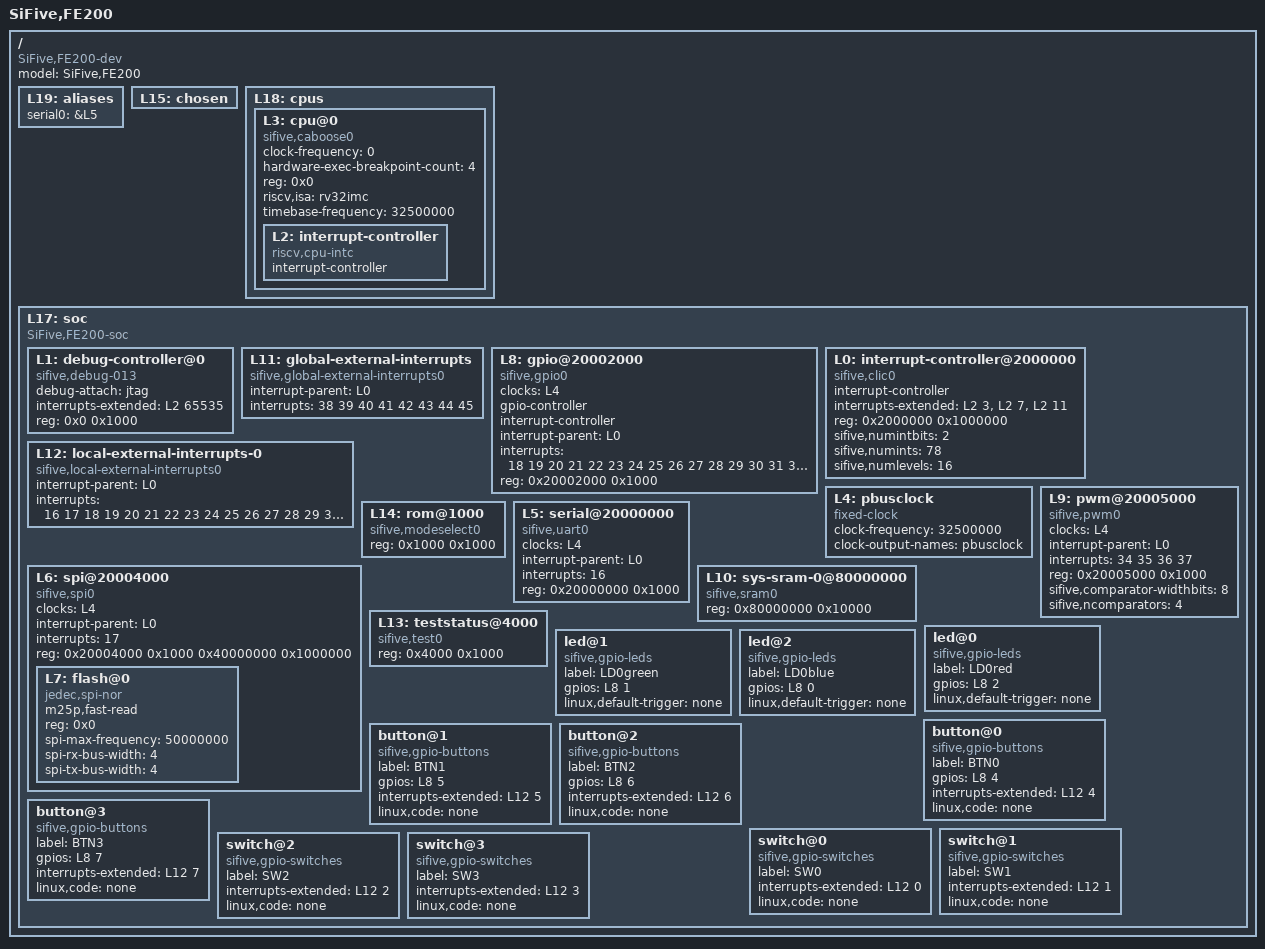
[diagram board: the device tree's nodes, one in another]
/dts-v1/;

/ {
	#address-cells = <1>;
	#size-cells = <1>;
	compatible = "SiFive,FE200-dev", "fe200-dev", "sifive-dev";
	model = "SiFive,FE200";
	L19: aliases {
		serial0 = &L5;
	};
	L15: chosen {
	};
	L18: cpus {
		#address-cells = <1>;
		#size-cells = <0>;
		L3: cpu@0 {
			clock-frequency = <0>;
			compatible = "sifive,caboose0", "riscv";
			device_type = "cpu";
			hardware-exec-breakpoint-count = <4>;
			reg = <0x0>;
			riscv,isa = "rv32imc";
			status = "okay";
			timebase-frequency = <32500000>;
			L2: interrupt-controller {
				#interrupt-cells = <1>;
				compatible = "riscv,cpu-intc";
				interrupt-controller;
			};
		};
	};
	L17: soc {
		#address-cells = <1>;
		#size-cells = <1>;
		compatible = "SiFive,FE200-soc", "fe200-soc", "sifive-soc", "simple-bus";
		ranges;
		L1: debug-controller@0 {
			compatible = "sifive,debug-013", "riscv,debug-013";
			debug-attach = "jtag";
			interrupts-extended = <&L2 65535>;
			reg = <0x0 0x1000>;
			reg-names = "control";
		};
		L11: global-external-interrupts {
			compatible = "sifive,global-external-interrupts0";
			interrupt-parent = <&L0>;
			interrupts = <38 39 40 41 42 43 44 45>;
		};
		L8: gpio@20002000 {
			#gpio-cells = <2>;
			#interrupt-cells = <2>;
			clocks = <&L4>;
			compatible = "sifive,gpio0", "sifive,gpio1";
			gpio-controller;
			interrupt-controller;
			interrupt-parent = <&L0>;
			interrupts = <18 19 20 21 22 23 24 25 26 27 28 29 30 31 32 33>;
			reg = <0x20002000 0x1000>;
			reg-names = "control";
		};
		L0: interrupt-controller@2000000 {
			#interrupt-cells = <1>;
			compatible = "sifive,clic0";
			interrupt-controller;
			interrupts-extended = <&L2 3 &L2 7 &L2 11>;
			reg = <0x2000000 0x1000000>;
			reg-names = "control";
			sifive,numintbits = <2>;
			sifive,numints = <78>;
			sifive,numlevels = <16>;
		};
		L12: local-external-interrupts-0 {
			compatible = "sifive,local-external-interrupts0";
			interrupt-parent = <&L0>;
			interrupts = <16 17 18 19 20 21 22 23 24 25 26 27 28 29 30 31 32 33 34 35 36 37 38 39 40 41 42 43 44 45 46 47>;
		};
		L4: pbusclock {
			#clock-cells = <0>;
			clock-frequency = <32500000>;
			clock-output-names = "pbusclock";
			compatible = "fixed-clock";
		};
		L9: pwm@20005000 {
			clocks = <&L4>;
			compatible = "sifive,pwm0";
			interrupt-parent = <&L0>;
			interrupts = <34 35 36 37>;
			reg = <0x20005000 0x1000>;
			reg-names = "control";
			sifive,comparator-widthbits = <8>;
			sifive,ncomparators = <4>;
		};
		L14: rom@1000 {
			compatible = "sifive,modeselect0";
			reg = <0x1000 0x1000>;
			reg-names = "mem";
		};
		L5: serial@20000000 {
			clocks = <&L4>;
			compatible = "sifive,uart0";
			interrupt-parent = <&L0>;
			interrupts = <16>;
			reg = <0x20000000 0x1000>;
			reg-names = "control";
		};
		L6: spi@20004000 {
			#address-cells = <1>;
			#size-cells = <0>;
			clocks = <&L4>;
			compatible = "sifive,spi0";
			interrupt-parent = <&L0>;
			interrupts = <17>;
			reg = <0x20004000 0x1000 0x40000000 0x1000000>;
			reg-names = "control", "mem";
			L7: flash@0 {
				compatible = "jedec,spi-nor";
				m25p,fast-read;
				reg = <0x0>;
				spi-max-frequency = <50000000>;
				spi-rx-bus-width = <4>;
				spi-tx-bus-width = <4>;
			};
		};
		L10: sys-sram-0@80000000 {
			compatible = "sifive,sram0";
			reg = <0x80000000 0x10000>;
			reg-names = "mem";
		};
		L13: teststatus@4000 {
			compatible = "sifive,test0";
			reg = <0x4000 0x1000>;
			reg-names = "control";
		};
				led@0 {
						compatible = "sifive,gpio-leds";
						label = "LD0red";
						gpios = <&L8 2>;
						linux,default-trigger = "none";
				};
				led@1 {
						compatible = "sifive,gpio-leds";
						label = "LD0green";
						gpios = <&L8 1>;
						linux,default-trigger = "none";
				};
				led@2 {
						compatible = "sifive,gpio-leds";
						label = "LD0blue";
						gpios = <&L8 0>;
						linux,default-trigger = "none";
				};
				button@0 {
						compatible = "sifive,gpio-buttons";
						label = "BTN0";
						gpios = <&L8 4>;
						interrupts-extended = <&L12 4>;
						linux,code = "none";
				};
				button@1 {
						compatible = "sifive,gpio-buttons";
						label = "BTN1";
						gpios = <&L8 5>;
						interrupts-extended = <&L12 5>;
						linux,code = "none";
				};
				button@2 {
						compatible = "sifive,gpio-buttons";
						label = "BTN2";
						gpios = <&L8 6>;
						interrupts-extended = <&L12 6>;
						linux,code = "none";
				};
				button@3 {
						compatible = "sifive,gpio-buttons";
						label = "BTN3";
						gpios = <&L8 7>;
						interrupts-extended = <&L12 7>;
						linux,code = "none";
				};
				switch@0 {
						compatible = "sifive,gpio-switches";
						label = "SW0";
						interrupts-extended = <&L12 0>;
						linux,code = "none";
				};
				switch@1 {
						compatible = "sifive,gpio-switches";
						label = "SW1";
						interrupts-extended = <&L12 1>;
						linux,code = "none";
				};
				switch@2 {
						compatible = "sifive,gpio-switches";
						label = "SW2";
						interrupts-extended = <&L12 2>;
						linux,code = "none";
				};
				switch@3 {
						compatible = "sifive,gpio-switches";
						label = "SW3";
						interrupts-extended = <&L12 3>;
						linux,code = "none";
				};

	};
};
